# STM32F105 register map
File version: 1.3
CPU: CM3 r1p1, little endian, no MPU, no FPU, 4 interrupt priority bits
Registers are 32-bit, read-write, reset 0x0 unless marked. A register's access mark holds for its fields unless they carry their own. Offsets are from the block's base; [hi:lo] are bit positions.

## I2C1 — Inter integrated circuit
Base 0x40005400
Same registers: I2C2 0x40005800
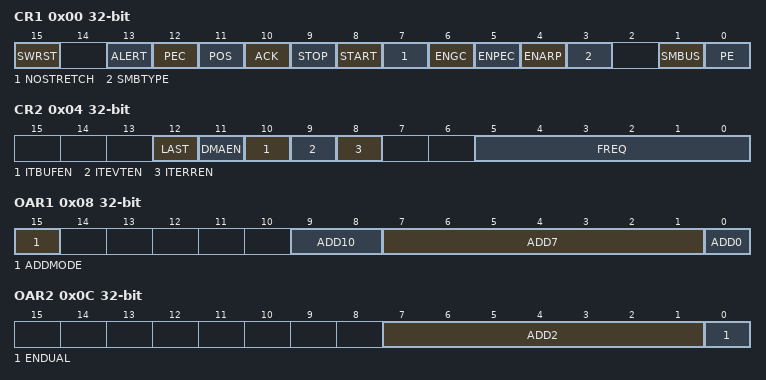
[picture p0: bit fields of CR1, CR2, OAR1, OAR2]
0x00 CR1 — Control register 1
  [15] SWRST — Software reset
  [13] ALERT — SMBus alert
  [12] PEC — Packet error checking
  [11] POS — Acknowledge/PEC Position (for data reception)
  [10] ACK — Acknowledge enable
  [9] STOP — Stop generation
  [8] START — Start generation
  [7] NOSTRETCH — Clock stretching disable (Slave mode)
  [6] ENGC — General call enable
  [5] ENPEC — PEC enable
  [4] ENARP — ARP enable
  [3] SMBTYPE — SMBus type
  [1] SMBUS — SMBus mode
  [0] PE — Peripheral enable
0x04 CR2 — Control register 2
  [12] LAST — DMA last transfer
  [11] DMAEN — DMA requests enable
  [10] ITBUFEN — Buffer interrupt enable
  [9] ITEVTEN — Event interrupt enable
  [8] ITERREN — Error interrupt enable
  [5:0] FREQ — Peripheral clock frequency
0x08 OAR1 — Own address register 1
  [15] ADDMODE — Addressing mode (slave mode)
  [9:8] ADD10 — Interface address
  [7:1] ADD7 — Interface address
  [0] ADD0 — Interface address
0x0C OAR2 — Own address register 2
  [7:1] ADD2 — Interface address
  [0] ENDUAL — Dual addressing mode enable
0x10 DR — Data register
  [7:0] DR — 8-bit data register
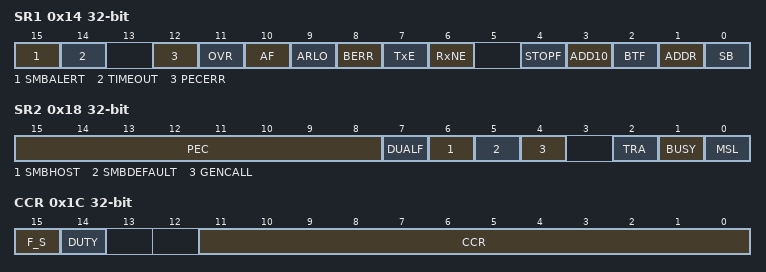
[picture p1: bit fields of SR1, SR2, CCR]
0x14 SR1 access per field — Status register 1
  [15] SMBALERT rw — SMBus alert
  [14] TIMEOUT rw — Timeout or Tlow error
  [12] PECERR rw — PEC Error in reception
  [11] OVR rw — Overrun/Underrun
  [10] AF rw — Acknowledge failure
  [9] ARLO rw — Arbitration lost (master mode)
  [8] BERR rw — Bus error
  [7] TxE ro — Data register empty (transmitters)
  [6] RxNE ro — Data register not empty (receivers)
  [4] STOPF ro — Stop detection (slave mode)
  [3] ADD10 ro — 10-bit header sent (Master mode)
  [2] BTF ro — Byte transfer finished
  [1] ADDR ro — Address sent (master mode)/matched (slave mode)
  [0] SB ro — Start bit (Master mode)
0x18 SR2 ro — Status register 2
  [15:8] PEC — acket error checking register
  [7] DUALF — Dual flag (Slave mode)
  [6] SMBHOST — SMBus host header (Slave mode)
  [5] SMBDEFAULT — SMBus device default address (Slave mode)
  [4] GENCALL — General call address (Slave mode)
  [2] TRA — Transmitter/receiver
  [1] BUSY — Bus busy
  [0] MSL — Master/slave
0x1C CCR — Clock control register
  [15] F_S — I2C master mode selection
  [14] DUTY — Fast mode duty cycle
  [11:0] CCR — Clock control register in Fast/Standard mode (Master mode)
0x20 TRISE reset 0x2
  [5:0] TRISE — Maximum rise time in Fast/Standard mode (Master mode)

## IWDG — Independent watchdog
Base 0x40003000
0x00 KR wo — Key register (IWDG_KR)
  [15:0] KEY — Key value
0x04 PR — Prescaler register (IWDG_PR)
  [2:0] PR — Prescaler divider
0x08 RLR reset 0xFFF — Reload register (IWDG_RLR)
  [11:0] RL — Watchdog counter reload value
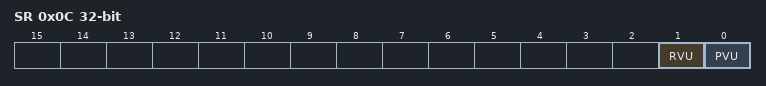
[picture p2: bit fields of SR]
0x0C SR ro — Status register (IWDG_SR)
  [1] RVU — Watchdog counter reload value update
  [0] PVU — Watchdog prescaler value update

## PWR — Power control
Base 0x40007000
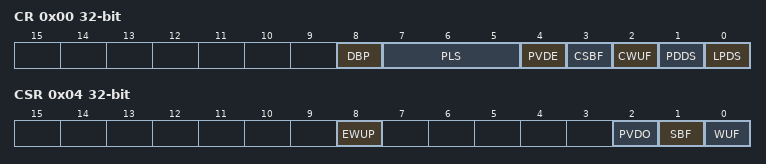
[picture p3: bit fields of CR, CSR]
0x00 CR — Power control register (PWR_CR)
  [8] DBP — Disable Backup Domain write protection
  [7:5] PLS — PVD Level Selection
  [4] PVDE — Power Voltage Detector Enable
  [3] CSBF — Clear STANDBY Flag
  [2] CWUF — Clear Wake-up Flag
  [1] PDDS — Power Down Deep Sleep
  [0] LPDS — Low Power Deep Sleep
0x04 CSR access per field — Power control register (PWR_CR)
  [8] EWUP rw — Enable WKUP pin
  [2] PVDO ro — PVD Output
  [1] SBF ro — STANDBY Flag
  [0] WUF ro — Wake-Up Flag

## RTC — Real time clock
Base 0x40002800
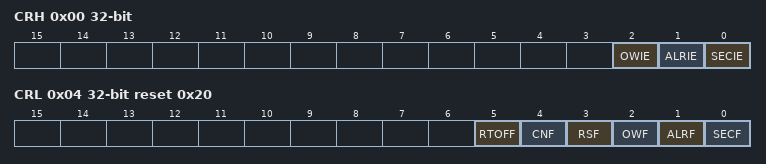
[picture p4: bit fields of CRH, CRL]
0x00 CRH — RTC Control Register High
  [2] OWIE — Overflow interrupt Enable
  [1] ALRIE — Alarm interrupt Enable
  [0] SECIE — Second interrupt Enable
0x04 CRL access per field reset 0x20 — RTC Control Register Low
  [5] RTOFF ro — RTC operation OFF
  [4] CNF rw — Configuration Flag
  [3] RSF rw — Registers Synchronized Flag
  [2] OWF rw — Overflow Flag
  [1] ALRF rw — Alarm Flag
  [0] SECF rw — Second Flag
0x08 PRLH wo — RTC Prescaler Load Register High
  [3:0] PRLH
0x0C PRLL wo reset 0x8000 — RTC Prescaler Load Register Low
  [15:0] PRLL — RTC Prescaler Divider Register Low
0x10 DIVH ro — RTC Prescaler Divider Register High
  [3:0] DIVH — RTC prescaler divider register high
0x14 DIVL ro reset 0x8000 — RTC Prescaler Divider Register Low
  [15:0] DIVL — RTC prescaler divider register Low
0x18 CNTH — RTC Counter Register High
  [15:0] CNTH — RTC counter register high
0x1C CNTL — RTC Counter Register Low
  [15:0] CNTL — RTC counter register Low
0x20 ALRH wo reset 0xFFFF — RTC Alarm Register High
  [15:0] ALRH — RTC alarm register high
0x24 ALRL wo reset 0xFFFF — RTC Alarm Register Low
  [15:0] ALRL — RTC alarm register low
